# V8M-Generic register map
Vendor: ARM Ltd.
V8M-Generic core descriptions, generated from ARM develloper studio
CPU: V8M-Generic r0p0, little endian, MPU, FPU, double-precision FPU, VTOR, vendor SysTick, 8 interrupt priority bits
Registers are 32-bit, read-write, no defined reset value unless marked. A register's access mark holds for its fields unless they carry their own. Offsets are from the block's base; lines under a group give offsets from that group; [hi:lo] are bit positions; {n}, {i} and the like mark numbered series; 'fields as' and 'values as' point back to an identical list; <NAME> marks a mode.

## Memory map
? FPE size 0x180 — Floating Point Control Registers
? CM size 0x140 — Cache Maintenance Operations
? ICB size 0x60 — Interrupt Control Registers
? DCB size 0xC0 — Debug Registers
? DIB size 0x220 — Identification Registers
? SCB size 0x890 — System Control Block
? NVIC size 0x1B80 — Nested Vectored Interrupt Controller
? MPU size 0x7E0 — Memory protection Unit Control Registers
? SIG size 0x20 — Software Interrupt Control
? SYST size 0x180 — SysTick Control Registers
? SAU size 0xE0 — Security Attribute Unit

## FPE — Floating Point Control Registers
Base ?
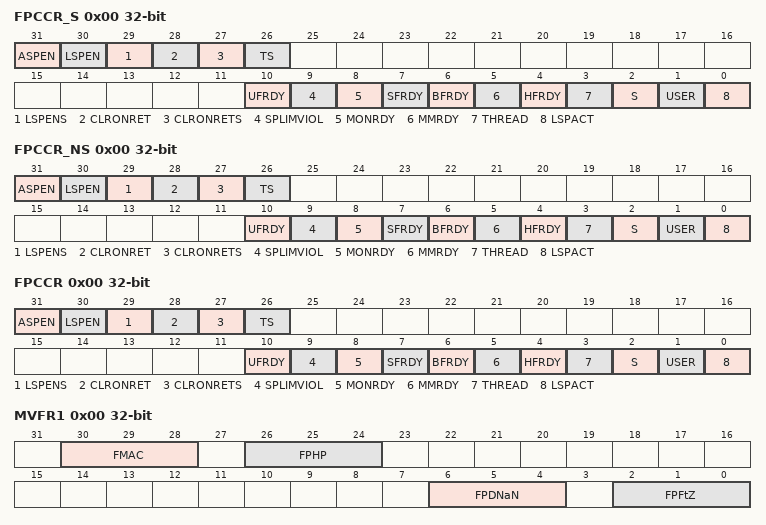
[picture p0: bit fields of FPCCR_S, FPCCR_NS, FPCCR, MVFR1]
0x00 FPCCR_S
  [31] ASPEN — When this bit is set to 1, execution of a floating-point instruction sets the CONTROL.FPCA bit to 1
  [30] LSPEN — Enables lazy context save of FP state
  [29] LSPENS — This bit controls whether the LSPEN bit is writeable from the Non-secure state. This behaves as RAZ/WI when accessed from the Non-secure state
  [28] CLRONRET — Clear floating point caller saved registers on exception return
  [27] CLRONRETS — CLRONRET Secure only
  [26] TS — Treat FP registers as Secure enable
  [10] UFRDY — Indicates whether the software executing when the processor allocated the FP stack frame was able to set the UsageFault exception to pending
  [9] SPLIMVIOL — This bit is banked between the Security states and indicates whether the FP context violates the stack pointer limit that was active when lazy state preservation was activated. SPLIMVIOL modifies the lazy FP state preservation behaviour
  [8] MONRDY — Indicates whether the software executing when the processor allocated the FP stack frame was able to set the DebugMonitor exception to pending
  [7] SFRDY — Indicates whether the software executing when the processor allocated the FP stack frame was able to set the SecureFault exception to pending. This bit is only present in the Secure version of the register, and behaves as RAZ/WI when accessed from the Non-secure state
  [6] BFRDY — Indicates whether the software executing when the processor allocated the FP stack frame was able to set the BusFault exception to pending
  [5] MMRDY — Indicates whether the software executing when the processor allocated the FP stack frame was able to set the MemManage exception to pending
  [4] HFRDY — Indicates whether the software executing when the processor allocated the FP stack frame was able to set the HardFault exception to pending
  [3] THREAD — Indicates the processor mode when it allocated the FP stack frame
  [2] S — Security status of the FP context. This bit is only present in the Secure version of the register, and behaves as RAZ/WI when accessed from the Non-secure state. This bit is updated whenever lazy state preservation is activated, or when a floating point instruction is executed
  [1] USER — Indicates the privilege level of the software executing when the processor allocated the FP stack frame
  [0] LSPACT — Indicates whether lazy preservation of the FP state is active
0x00 FPCCR_NS
  fields as FPCCR_S
0x00 FPCCR
  fields as FPCCR_S
0x00 MVFR1 ro
  [30:28] FMAC — Fused multiply accumulate
  [26:24] FPHP — Floating-point half-precision
  [6:4] FPDNaN — Floating-point default NaN
  [2:0] FPFtZ — Floating-point flush-to-zero
0x04 FPCAR_S
  [30:3] ADDRESS
0x04 FPCAR_NS
  [30:3] ADDRESS
0x04 FPCAR
  [30:3] ADDRESS
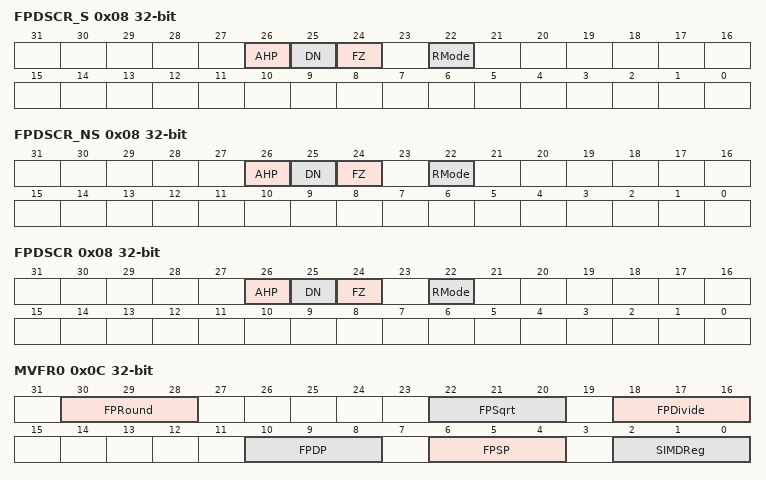
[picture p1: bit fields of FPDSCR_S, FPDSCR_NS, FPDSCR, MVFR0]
0x08 FPDSCR_S
  [26] AHP — Alternative half-precision
  [25] DN — Default NaN
  [24] FZ — Flush-to-zero
  [22] RMode — Rounding mode
0x08 FPDSCR_NS
  fields as FPDSCR_S
0x08 FPDSCR
  fields as FPDSCR_S
0x0C MVFR0 ro
  [30:28] FPRound — Floating-point rounding modes
  [22:20] FPSqrt — Floating-point square root
  [18:16] FPDivide — Floating-point divide
  [10:8] FPDP — Floating-point double-precision
  [6:4] FPSP — Floating-point single-precision
  [2:0] SIMDReg — SIMD registers
0x14 MVFR2 ro
  [6:4] FPMisc — Floating-point miscellaneous
